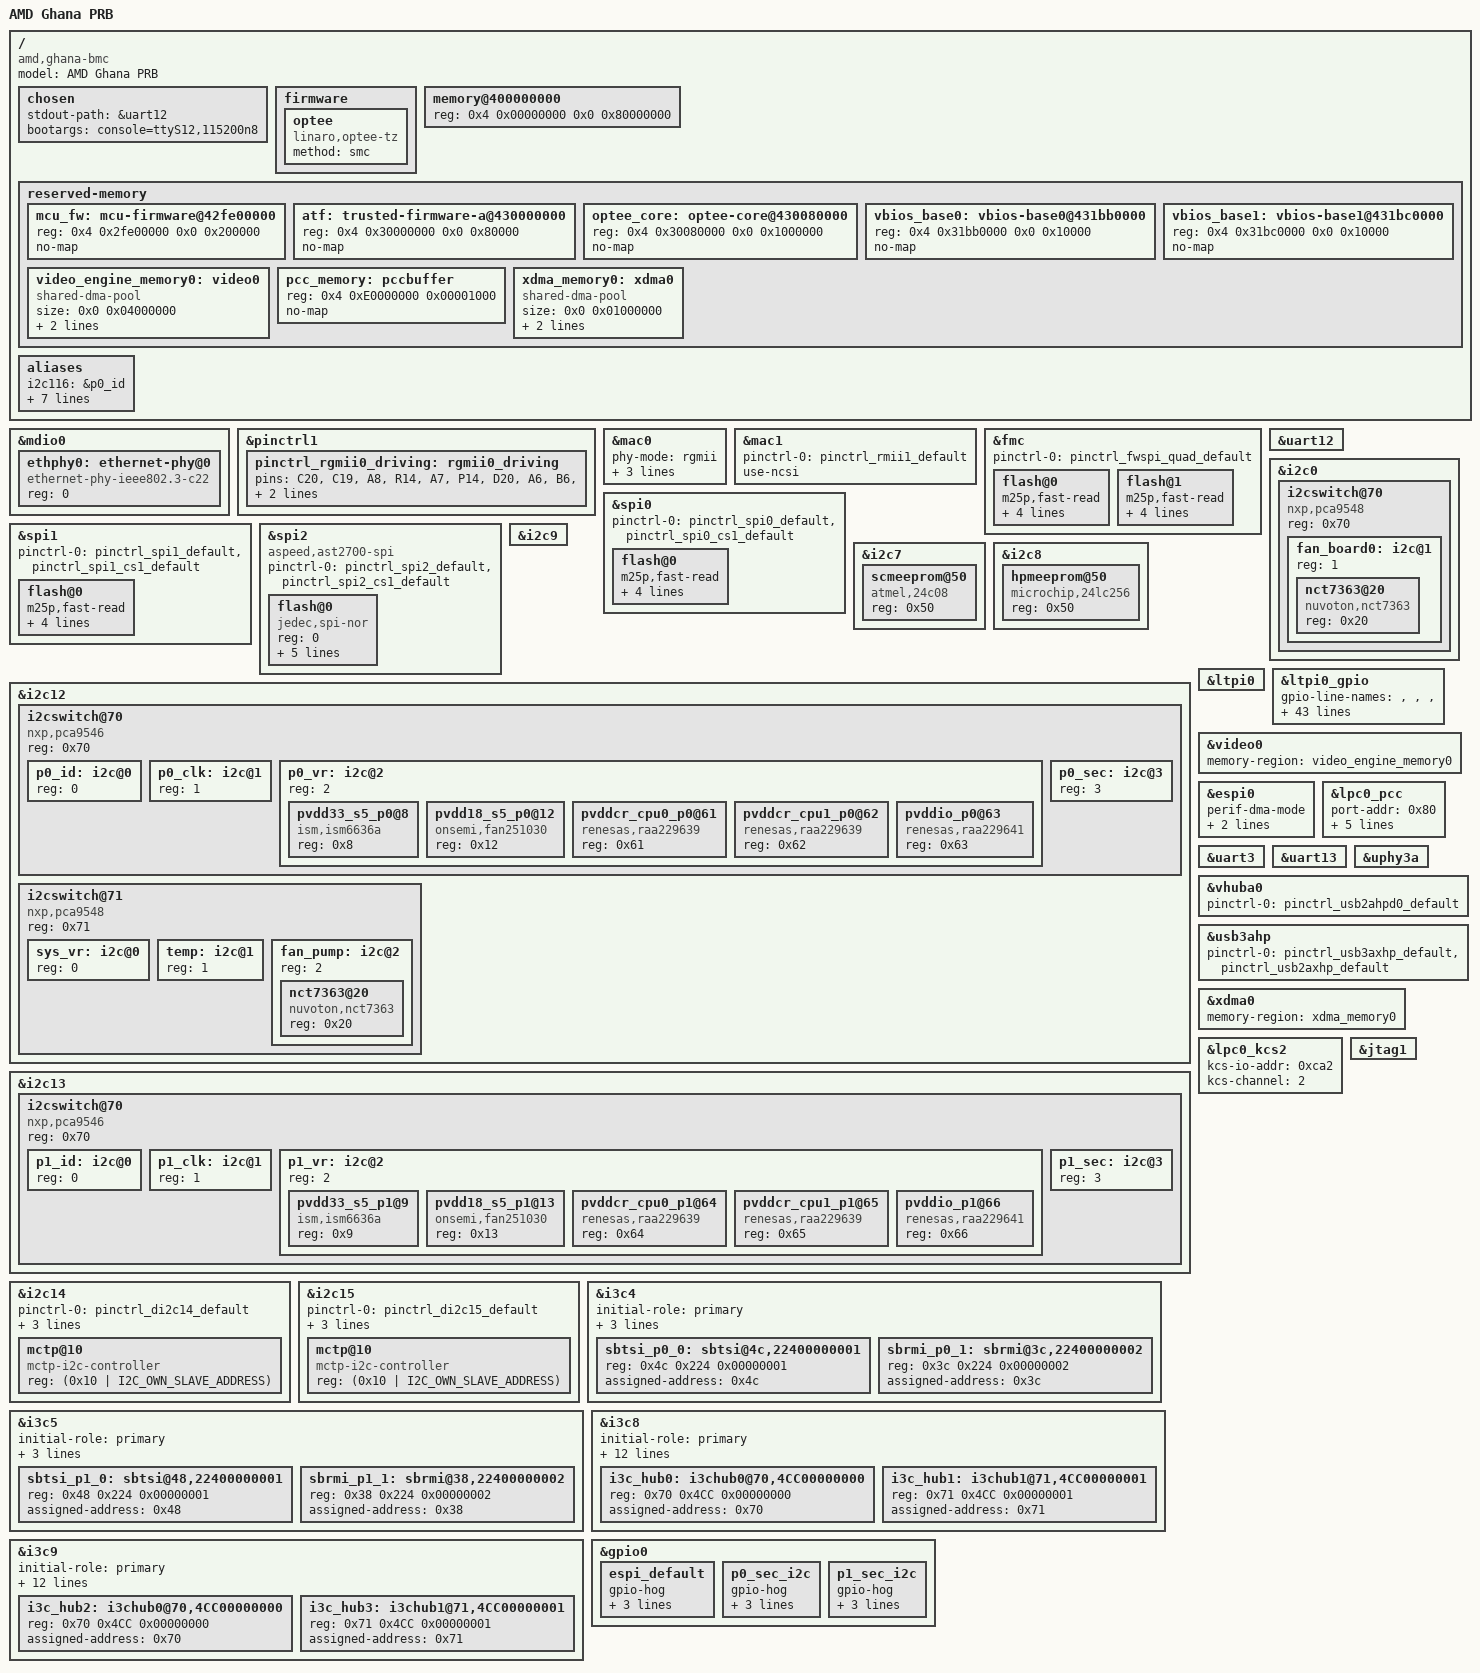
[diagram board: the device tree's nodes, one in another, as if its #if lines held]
// SPDX-License-Identifier: GPL-2.0
// Copyright (c) 2024 AMD Inc.
// Author: Mahesh Kurapati <mahesh.kurapati@amd.com>
//         Mohsen Dolaty <mohsen.dolaty@amd.com>

/dts-v1/;

#include "aspeed-g7.dtsi"
#include "dt-bindings/gpio/aspeed-gpio.h"
#include <dt-bindings/i2c/i2c.h>
#include <dt-bindings/i3c/i3c.h>

/ {
	model = "AMD Ghana PRB";
	compatible = "amd,ghana-bmc", "aspeed,ast2700";

	chosen {
		stdout-path = &uart12;
		bootargs = "console=ttyS12,115200n8";
	};

	firmware {
		optee: optee {
			compatible = "linaro,optee-tz";
			method = "smc";
		};
	};

	memory@400000000 {
		device_type = "memory";
		reg = <0x4 0x00000000 0x0 0x80000000>;
	};

	reserved-memory {
		#address-cells = <2>;
		#size-cells = <2>;
		ranges;

		mcu_fw: mcu-firmware@42fe00000 {
			reg = <0x4 0x2fe00000 0x0 0x200000>;
			no-map;
		};

		atf: trusted-firmware-a@430000000 {
			reg = <0x4 0x30000000 0x0 0x80000>;
			no-map;
		};

		optee_core: optee-core@430080000 {
			reg = <0x4 0x30080000 0x0 0x1000000>;
			no-map;
		};

		vbios_base0: vbios-base0@431bb0000 {
			reg = <0x4 0x31bb0000 0x0 0x10000>;
			no-map;
		};

		vbios_base1: vbios-base1@431bc0000 {
			reg = <0x4 0x31bc0000 0x0 0x10000>;
			no-map;
		};

		video_engine_memory0: video0 {
			size = <0x0 0x04000000>;  /* 64M */
			alignment = <0x0 0x00010000>;
			compatible = "shared-dma-pool";
			reusable;
		};

		pcc_memory: pccbuffer {
			reg = <0x4 0xE0000000 0x00001000>; /* 4K */
			no-map;
		};

		xdma_memory0: xdma0 {
			size = <0x0 0x01000000>;
			alignment = <0x0 0x01000000>;
			compatible = "shared-dma-pool";
			no-map;
		};
	};

	aliases {
		i2c116 = &p0_id;
		i2c117 = &p0_clk;
		i2c118 = &p0_vr;
		i2c119 = &p0_sec;
		i2c120 = &sys_vr;
		i2c121 = &temp;
		i2c122 = &fan_pump;
		i2c203 = &fan_board0;
	};
};

&mdio0 {
	status = "okay";
	#address-cells = <1>;
	#size-cells = <0>;

	ethphy0: ethernet-phy@0 {
		compatible = "ethernet-phy-ieee802.3-c22";
		reg = <0>;
	};
};

&pinctrl1 {
	pinctrl_rgmii0_driving: rgmii0_driving {
		pins = "C20", "C19", "A8", "R14", "A7", "P14",
		       "D20", "A6", "B6", "N14", "B7", "B8";
		drive-strength = <1>;
	};
};

&mac0 {
	status = "okay";
	phy-mode = "rgmii";
	phy-handle = <&ethphy0>;
	pinctrl-names = "default";
	pinctrl-0 = <&pinctrl_rgmii0_default &pinctrl_rgmii0_driving>;
};

&mac1 {
        status = "okay";
        pinctrl-names = "default";
        pinctrl-0 = <&pinctrl_rmii1_default>;
        clock-names = "MACCLK", "RCLK";
        use-ncsi;
};

&fmc {
	status = "okay";
	pinctrl-0 = <&pinctrl_fwspi_quad_default>;
	pinctrl-names = "default";

	flash@0 {
		status = "okay";
		m25p,fast-read;
		label = "bmc";
		spi-max-frequency = <50000000>;
		spi-tx-bus-width = <4>;
		spi-rx-bus-width = <4>;
#include "amd-flash-layout-128.dtsi"
	};

	flash@1 {
		status = "okay";
		m25p,fast-read;
		label = "mpflash";
		spi-max-frequency = <50000000>;
		spi-tx-bus-width = <4>;
		spi-rx-bus-width = <4>;
	};
};

&spi0 {
	status = "okay";
	pinctrl-0 = <&pinctrl_spi0_default &pinctrl_spi0_cs1_default>;
	pinctrl-names = "default";

	flash@0 {
		status = "okay";
		m25p,fast-read;
		label = "pnor";
		spi-max-frequency = <33000000>;
		spi-tx-bus-width = <1>;
		spi-rx-bus-width = <1>;
	};
};

&spi1 {
	status = "okay";
	pinctrl-0 = <&pinctrl_spi1_default &pinctrl_spi1_cs1_default>;
	pinctrl-names = "default";

	flash@0 {
		status = "okay";
		m25p,fast-read;
		label = "pnor";
		spi-max-frequency = <33000000>;
		spi-tx-bus-width = <1>;
		spi-rx-bus-width = <1>;
	};
};

&spi2 {
	status = "okay";
	pinctrl-0 = <&pinctrl_spi2_default &pinctrl_spi2_cs1_default>;
	pinctrl-names = "default";
	compatible = "aspeed,ast2700-spi";

	flash@0 {
		reg = <0>;
		status = "okay";
		m25p,fast-read;
		label = "pnor";
		compatible = "jedec,spi-nor";
		spi-max-frequency = <16000000>;
		spi-tx-bus-width = <1>;
		spi-rx-bus-width = <1>;
	};
};

//BMC Console
&uart12 {
	status = "okay";
};

&i2c0 {
	// FPGA_I2C_SDA<2>
	/delete-property/ pinctrl-names;
	/delete-property/ pinctrl-0;
	status = "okay";

	i2cswitch@70 {
		compatible = "nxp,pca9548";
		reg = <0x70>;
		#address-cells = <1>;
		#size-cells = <0>;

		fan_board0: i2c@1 {
			reg = <1>;
			#address-cells = <1>;
			#size-cells = <0>;
			nct7363@20 {
				compatible = "nuvoton,nct7363";
				reg = <0x20>;
			};
		};
	};
};

&i2c7 {
	status = "okay";
	scmeeprom@50 {
		compatible = "atmel,24c08";
		reg = <0x50>;
	};
};

&i2c8 {
	// Net name SCM_I2C<0>
	status = "okay";
	hpmeeprom@50 {
		compatible = "microchip,24lc256","atmel,24c256";
		reg = <0x50>;
	};
};

&i2c9 {
	// Net name SCM_I2C<1>
	status = "okay";
};

&i2c12 {
	// Net name i2c2 (SCM_I2C_SDA<2>)
	status = "okay";

	i2cswitch@70 {
		compatible = "nxp,pca9546";
		reg = <0x70>;
		#address-cells = <1>;
		#size-cells = <0>;

		p0_id: i2c@0 {
			reg = <0>;
			#address-cells = <1>;
			#size-cells = <0>;
		};

		p0_clk: i2c@1 {
			reg = <1>;
			#address-cells = <1>;
			#size-cells = <0>;
		};

		p0_vr: i2c@2 {
			reg = <2>;
			#address-cells = <1>;
			#size-cells = <0>;

			pvdd33_s5_p0@8{
				compatible = "ism,ism6636a";
				reg = <0x8>;
			};
                        pvdd18_s5_p0@12{
                                compatible = "onsemi,fan251030";
                                reg = <0x12>;
                        };
			pvddcr_cpu0_p0@61 {
				//PVDDCR_CPU0_VDDIO_MEM_S3_P0_CONTROLLER
				compatible = "renesas,raa229639";
				reg = <0x61>;
			};
			pvddcr_cpu1_p0@62 {
				//PVDDCR_CPU1_PVDDCR_SOC_P0_CONTROLLER
				compatible = "renesas,raa229639";
				reg = <0x62>;
			};
			pvddio_p0@63 {
				//PVDDIO_P0_CONTROLLER
				compatible = "renesas,raa229641";
				reg = <0x63>;
			};
		};

		p0_sec: i2c@3 {
			reg = <3>;
			#address-cells = <1>;
			#size-cells = <0>;
		};
	};

	i2cswitch@71 {
		compatible = "nxp,pca9548";
		reg = <0x71>;
		#address-cells = <1>;
		#size-cells = <0>;

		sys_vr: i2c@0 {
			reg = <0>;
			#address-cells = <1>;
			#size-cells = <0>;
/*
			p2v5_aux@9{
				compatible = "ism,ism6636c";
				reg = <0x9>;
			};
			p1v8_aux@a{
				compatible = "ism,ism6636c";
				reg = <0xa>;
			};
			p1v0_aux@b{
				compatible = "ism,ism6636c";
				reg = <0xb>;
			};
			p5v_aux@14{
				compatible = "onsemi,fan251030";
				reg = <0x14>;
			};
			p3v3_aux@15{
				compatible = "onsemi,fan251030";
				reg = <0x15>;
			};
			p3v3@16{
				compatible = "onsemi,fan251030";
				reg = <0x16>;
			};
*/
		};

		temp: i2c@1 {
			reg = <1>;
			#address-cells = <1>;
			#size-cells = <0>;
		};

		fan_pump: i2c@2 {
			reg = <2>;
			#address-cells = <1>;
			#size-cells = <0>;

			nct7363@20 {
				compatible = "nuvoton,nct7363";
				reg = <0x20>;
			};
		};
	};
};

&i2c13 {
        // Net name i2c3 (SCM_I2C_SDA<3>)
        status = "okay";

        i2cswitch@70 {
                compatible = "nxp,pca9546";
                reg = <0x70>;
                #address-cells = <1>;
                #size-cells = <0>;

                p1_id: i2c@0 {
                        reg = <0>;
                        #address-cells = <1>;
                        #size-cells = <0>;
                };

                p1_clk: i2c@1 {
                        reg = <1>;
                        #address-cells = <1>;
                        #size-cells = <0>;
                };

                p1_vr: i2c@2 {
                        reg = <2>;
                        #address-cells = <1>;
                        #size-cells = <0>;

			pvdd33_s5_p1@9 {
				compatible = "ism,ism6636a";
				reg = <0x9>;
			};
			pvdd18_s5_p1@13{
				compatible = "onsemi,fan251030";
				reg = <0x13>;
			};
			pvddcr_cpu0_p1@64 {
				//PVDDCR_CPU0_VDDIO_MEM_S3_P0_CONTROLLER
				compatible = "renesas,raa229639";
				reg = <0x64>;
			};
			pvddcr_cpu1_p1@65 {
				//PVDDCR_CPU1_PVDDCR_SOC_P0_CONTROLLER
				compatible = "renesas,raa229639";
				reg = <0x65>;
			};
			pvddio_p1@66 {
				//PVDDIO_P0_CONTROLLER
				compatible = "renesas,raa229641";
				reg = <0x66>;
			};
                };

                p1_sec: i2c@3 {
                        reg = <3>;
                        #address-cells = <1>;
                        #size-cells = <0>;
                };
        };
};

/* P1-SEC */
&i2c14 {
        status = "okay";
        pinctrl-0 = <&pinctrl_di2c14_default>;
        clock-frequency = <400000>;

        multi-master;
        mctp-controller;
        mctp@10 {
                compatible = "mctp-i2c-controller";
                reg = <(0x10 | I2C_OWN_SLAVE_ADDRESS)>;
        };
};

/* P0-SEC */
&i2c15 {
        status = "okay";
        pinctrl-0 = <&pinctrl_di2c15_default>;
        clock-frequency = <400000>;

        multi-master;
        mctp-controller;
        mctp@10 {
                compatible = "mctp-i2c-controller";
                reg = <(0x10 | I2C_OWN_SLAVE_ADDRESS)>;
        };
};

&i3c4 {
	status = "okay";
	initial-role = "primary";
	internal-pullup = <2>;
	i3c-scl-hz = <10000000>;
	i2c-scl-hz = <1000000>;
#ifdef VERONA
	sbtsi_p0_0: sbtsi@4c,22400000001 {
		reg = <0x4c 0x224 0x00000001>;
		assigned-address = <0x4c>;
	};
	sbrmi_p0_1: sbrmi@3c,22400000002 {
		reg = <0x3c 0x224 0x00000002>;
		assigned-address = <0x3c>;
	};
#else
	mctp-controller;

	sbtsi_p0_iod0: sbtsi@4c,22400000118 {
		reg = <0x4c 0x224 0x00000118>;
		assigned-address = <0x4c>;
	};

	sbtsi_p0_iod1: sbtsi@44,22400010118 {
		reg = <0x44 0x224 0x00010118>;
		assigned-address = <0x44>;
	};

	sbrmi_p0_iod0: sbrmi@3c,22400001118 {
		reg = <0x3c 0x224 0x00001118>;
		assigned-address = <0x3c>;
	};

	scoob_p0: scoob@5c,22400002118 {
		reg = <0x5c 0x224 0x00002118>;
		assigned-address = <0x5c>;
	};
#endif
};

&i3c5 {
	status = "okay";
	initial-role = "primary";
	internal-pullup = <2>;
	i3c-scl-hz = <10000000>;
	i2c-scl-hz = <1000000>;
#ifdef VERONA
	sbtsi_p1_0: sbtsi@48,22400000001 {
		reg = <0x48 0x224 0x00000001>;
		assigned-address = <0x48>;
	};
	sbrmi_p1_1: sbrmi@38,22400000002 {
		reg = <0x38 0x224 0x00000002>;
		assigned-address = <0x38>;
	};
#else
	mctp-controller;

	sbtsi_p1_iod0: sbtsi@48,22401000118 {
		reg = <0x48 0x224 0x01000118>;
		assigned-address = <0x48>;
	};

	sbtsi_p1_iod1: sbtsi@45,22401010118 {
		reg = <0x45 0x224 0x01010118>;
		assigned-address = <0x45>;
	};

	sbrmi_p1_iod0: sbrmi@38,22401011118 {
		reg = <0x38 0x224 0x01011118>;
		assigned-address = <0x38>;
	};

	scoob_p1: scoob@55,22401012118 {
		reg = <0x55 0x224 0x01012118>;
		assigned-address = <0x55>;
	};
#endif
};

#ifdef I3C_HUB

#define JESD300_SPD_I3C_MODE(bus, index, addr) \
spd_ ## bus ## _ ## index: spd@addr,4cc5118 ## index ## 000 { \
	reg = <0x ## addr 0x4cc 0x5118 ## index ## 000>; \
	assigned-address = <0x ## addr>; \
	dcr = /bits/ 8 <0xda>; \
	bcr = /bits/ 8 <0x6>; \
}

&i3c8 {
	status = "okay";
	initial-role = "primary";
	bus-context = /bits/ 8 <I3C_BUS_CONTEXT_JESD403>;
	internal-pullup = <2>;
	i3c-scl-hz = <10000000>;
	i2c-scl-hz = <1000000>;

	i3c_hub0: i3chub0@70,4CC00000000 {
		reg = <0x70 0x4CC 0x00000000>;
		assigned-address = <0x70>;
	};
	i3c_hub1: i3chub1@71,4CC00000001 {
		reg = <0x71 0x4CC 0x00000001>;
		assigned-address = <0x71>;
	};
	JESD300_SPD_I3C_MODE(0, 0, 50);
	JESD300_SPD_I3C_MODE(0, 1, 51);
	JESD300_SPD_I3C_MODE(0, 2, 52);
	JESD300_SPD_I3C_MODE(0, 3, 53);
	JESD300_SPD_I3C_MODE(0, 4, 54);
	JESD300_SPD_I3C_MODE(0, 5, 55);
	JESD300_SPD_I3C_MODE(0, 6, 56);
	JESD300_SPD_I3C_MODE(0, 7, 57);
};

&i3c9 {
	status = "okay";
	initial-role = "primary";
	bus-context = /bits/ 8 <I3C_BUS_CONTEXT_JESD403>;
	internal-pullup = <2>;
	i3c-scl-hz = <10000000>;
	i2c-scl-hz = <1000000>;

	i3c_hub2: i3chub0@70,4CC00000000 {
		reg = <0x70 0x4CC 0x00000000>;
		assigned-address = <0x70>;
	};
	i3c_hub3: i3chub1@71,4CC00000001 {
		reg = <0x71 0x4CC 0x00000001>;
		assigned-address = <0x71>;
	};
	JESD300_SPD_I3C_MODE(1, 0, 50);
	JESD300_SPD_I3C_MODE(1, 1, 51);
	JESD300_SPD_I3C_MODE(1, 2, 52);
	JESD300_SPD_I3C_MODE(1, 3, 53);
	JESD300_SPD_I3C_MODE(1, 4, 54);
	JESD300_SPD_I3C_MODE(1, 5, 55);
	JESD300_SPD_I3C_MODE(1, 6, 56);
	JESD300_SPD_I3C_MODE(1, 7, 57);
};
#endif

&gpio0 {
	status = "okay";
	espi_default {
		gpio-hog;
		gpios = <10 GPIO_ACTIVE_HIGH>;
		output-low;
		line-name = "espiboot_pin_default";
	};

	/*
         * by default the direction of the SEL_P0_SEC_I2C_ROT_BMC (GPIO B0)
         * is "in". It should be set to "out" and value of "1" for the
         * I2C bus to be owned by the BMC.
         */
        p0_sec_i2c {
                gpio-hog;
                gpios = <8 GPIO_ACTIVE_HIGH>;
                output-high;
                line-name = "SEL_P0_SEC_I2C_ROT_BMC";
        };

        /*
         * by default the direction of the SEL_P1_SEC_I2C_ROT_BMC (GPIO B1)
         * is "in". It should be set to "out" and value of "1" for the
         * I2C bus to be owned by the BMC.
         */
        p1_sec_i2c {
                gpio-hog;
                gpios = <9 GPIO_ACTIVE_HIGH>;
                output-high;
                line-name = "SEL_P1_SEC_I2C_ROT_BMC";
        };
};

&ltpi0 {
	status = "okay";
};

&ltpi0_gpio {
	status = "okay";
	gpio-line-names =
		/*00-07*/ "","","",
			"P0_MGMT_ASSERT_CLR_CMOS","P0_MGMT_MON_PROCHOT_L","P0_MGMT_ASSERT_PROCHOT_L",
			"P0_MGMT_MON_RSMRST_L","P0_ASSERT_RSMRST",
		/*08-15*/ "P0_MGMT_MON_THERMTRIP_L","P0_MGMT_ASSERT_THERMTRIP_L","P0_PRESENT_L",
			"","P1_PRESENT_L","",
			"P0_MGMT_MON_POST_COMPLETE","",
		/*16-23*/ "P0_MGMT_MON_PWR_GOOD","","P0_MGMT_MON_PSP_SOFT_FUSE_NTFY",
			"","P0_I3C_APML_ALERT_L","",
			"MGMT_SYS_MON_ATX_PWR_OK","",
		/*24-31*/ "","","","","","","","P0_MGMT_ASSERT_NMI_BTN_L",
		/*32-39*/ "","P0_MGMT_SOC_RESET_L","",
			"MGMT_HDT_SEL","","SCM_JTAG_DBREQ","","JTAG_TRST_N",
		/*40-47*/ "","P0_MGMT_ASSERT_WARM_RST_BTN_L","","","","","","",
                /*48-55*/ "","","P1_MGMT_MON_THERMTRIP_L","P1_MGMT_ASSERT_THERMTRIP",
			"P1_MGMT_MON_PROCHOT_L","P1_MGMT_ASSERT_PROCHOT",
			"P1_MGMT_MON_RSMRST_L","P1_ASSERT_RSMRST",
		/*56-63*/ "","","","","","","","",
		/*64-71*/ "","","","","","","","",
		/*72-79*/ "P1_MGMT_MON_POST_COMPLETE","","","","","","","",
		/*80-87*/ "P1_MGMT_MON_PSP_SOFT_FUSE_NOTIFY","","P1_MGMT_MON_PWR_GOOD","","","","","",
		/*88-95*/ "","","","","","","","P1_MGMT_ASSERT_WARM_RST_BTN_L",
		/*96-103*/ "","P1_MGMT_SOC_RESET_L","","P1_MGMT_ASSERT_NMI_BTN_L","",
			"P1_MGMT_ASSERT_CLR_CMOS","MGMT_MON_PLATFORM_CONFIG","MGMT_ASSERT_PLATFORM_CONFIG",
		/*104-111*/ "","","","","","HPM_STBY_EN","","",
		/*112-119*/ "","","","","","","","",
		/*120-127*/ "","","","","","","","",
		/*128-135*/ "P0_MGMT_MON_RST_BTN_L","P0_MGMT_ASSERT_RST_BTN_L","P0_MGMT_MON_PWR_BTN_L",
			"P0_MGMT_ASSERT_PWR_BTN_L","P1_MGMT_MON_RST_BTN_L","P1_MGMT_ASSERT_RST_BTN_L",
			"P1_MGMT_MON_PWR_BTN_L","P1_MGMT_ASSERT_PWR_BTN_L",
		/*136-143*/ "","","","","","","","",
		/*144-151*/ "","","","","","","","",
		/*152-159*/ "","","","","","","","",
		/*160-167*/ "","","","","","","","",
		/*168-175*/ "","","","","","","","",
		/*176-183*/ "","","","","","","","",
		/*184-191*/ "","","","","","","","",
		/*192-199*/ "","","","","","","","",
		/*200-207*/ "","","","","","","","",
		/*208-215*/ "","","","","","","","",
		/*216-223*/ "","","","","","","","";
};

&video0 {
	status = "okay";
	memory-region = <&video_engine_memory0>;
};

&espi0 {
	status = "okay";
	perif-dma-mode;
	oob-dma-mode;
	flash-dma-mode;
};

&lpc0_pcc {
	port-addr = <0x80>;
	dma-mode;
	A2600-15;
	rec-mode = <0x1>;
	port-addr-hbits-select = <0x1>;
	port-addr-xbits = <0x3>;
	status = "okay";
};

&uart3 {
	/delete-property/ pinctrl-names;
	/delete-property/ pinctrl-0;
	status = "okay";
};

&uart13 {
	/delete-property/ pinctrl-names;
	/delete-property/ pinctrl-0;
	status = "okay";
};

&uphy3a {
	status = "okay";
};

&vhuba0 {
	status = "okay";
	pinctrl-0 = <&pinctrl_usb2ahpd0_default>;
};

&usb3ahp {
	status = "okay";
	pinctrl-0 = <&pinctrl_usb3axhp_default &pinctrl_usb2axhp_default>;
};

&xdma0 {
	status = "okay";
	memory-region = <&xdma_memory0>;
};

&lpc0_kcs2 {
	status = "okay";
	kcs-io-addr = <0xca2>;
	kcs-channel = <2>;
};

&jtag1 {
	status = "okay";
};
